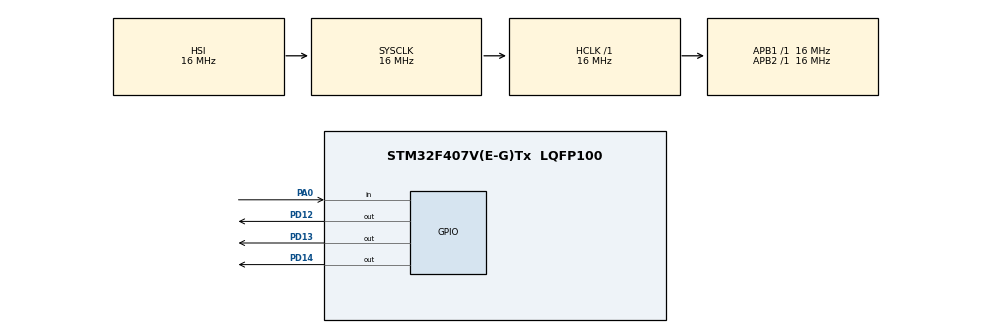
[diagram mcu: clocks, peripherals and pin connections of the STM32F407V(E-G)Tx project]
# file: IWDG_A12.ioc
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Mcu.Family=STM32F4
RCC.CortexFreq_Value=16000000
VP_IWDG_VS_IWDG.Mode=IWDG_Activate
ProjectManager.StackSize=0x400
PA0-WKUP.Signal=GPIO_Input
PD13.Signal=GPIO_Output
PA13.Signal=SYS_JTMS-SWDIO
ProjectManager.TargetToolchain=STM32CubeIDE
RCC.LSE_VALUE=32768
RCC.AHBFreq_Value=16000000
RCC.HSE_VALUE=25000000
board=custom
RCC.VCOOutputFreq_Value=192000000
RCC.APB2Freq_Value=16000000
VP_TIM2_VS_ClockSourceINT.Mode=Internal
PA14.Mode=Serial_Wire
NVIC.TIM2_IRQn=true\:0\:0\:false\:false\:true\:true\:true
TIM2.Period=50
PA13.Mode=Serial_Wire
Mcu.Name=STM32F407V(E-G)Tx
PD14.Signal=GPIO_Output
RCC.SYSCLKFreq_VALUE=16000000
Mcu.Package=LQFP100
TIM2.Prescaler=16000
PD12.Signal=GPIO_Output
PA14.Signal=SYS_JTCK-SWCLK
ProjectManager.HeapSize=0x200
RCC.HSI_VALUE=16000000
NVIC.PriorityGroup=NVIC_PRIORITYGROUP_4
TIM2.TIM_MasterOutputTrigger=TIM_TRGO_UPDATE
IWDG.Prescaler=IWDG_PRESCALER_64
RCC.APB1Freq_Value=16000000

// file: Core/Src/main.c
/* USER CODE BEGIN Header */
/**
  ******************************************************************************
  * @file           : main.c
  * @brief          : Main program body
  ******************************************************************************
  * @attention
  *
  * <h2><center>&copy; Copyright (c) 2021 STMicroelectronics.
  * All rights reserved.</center></h2>
  *
  * This software component is licensed by ST under BSD 3-Clause license,
  * the "License"; You may not use this file except in compliance with the
  * License. You may obtain a copy of the License at:
  *                        opensource.org/licenses/BSD-3-Clause
  *
  ******************************************************************************
  */
/* USER CODE END Header */
#include "main.h"

IWDG_HandleTypeDef hiwdg;

TIM_HandleTypeDef htim2;

/* USER CODE BEGIN PV */
uint32_t counter=0;
/* USER CODE END PV */

void SystemClock_Config(void);
static void MX_GPIO_Init(void);
static void MX_IWDG_Init(void);
static void MX_TIM2_Init(void);

int main(void)
{

  /* MCU Configuration--------------------------------------------------------*/

  /* Reset of all peripherals, Initializes the Flash interface and the Systick. */
  HAL_Init();

  /* Configure the system clock */
  SystemClock_Config();

  /* Initialize all configured peripherals */
  MX_GPIO_Init();
  MX_IWDG_Init();
  MX_TIM2_Init();
  /* USER CODE BEGIN 2 */
  HAL_GPIO_WritePin(GPIOD,GPIO_PIN_14,SET); // For Showing System Reset
  HAL_Delay(2500);
  HAL_TIM_Base_Start_IT(&htim2);
  HAL_GPIO_WritePin(GPIOD,GPIO_PIN_14,RESET);
  /* USER CODE END 2 */

  /* Infinite loop */
  while (1)
  {

    /* USER CODE BEGIN 3 */
	  if(HAL_GPIO_ReadPin(GPIOA,GPIO_PIN_0))
	  	  	  {
	  	  		  HAL_IWDG_Refresh(&hiwdg);
	  	  		  HAL_GPIO_TogglePin(GPIOD,GPIO_PIN_13); //WatchDog Refresh LED
	  	  	  }
  }
  /* USER CODE END 3 */
}

void SystemClock_Config(void)
{
  RCC_OscInitTypeDef RCC_OscInitStruct = {0};
  RCC_ClkInitTypeDef RCC_ClkInitStruct = {0};

  /** Configure the main internal regulator output voltage
  */
  __HAL_RCC_PWR_CLK_ENABLE();
  __HAL_PWR_VOLTAGESCALING_CONFIG(PWR_REGULATOR_VOLTAGE_SCALE1);
  /** Initializes the RCC Oscillators according to the specified parameters
  * in the RCC_OscInitTypeDef structure.
  */
  RCC_OscInitStruct.OscillatorType = RCC_OSCILLATORTYPE_HSI|RCC_OSCILLATORTYPE_LSI;
  RCC_OscInitStruct.HSIState = RCC_HSI_ON;
  RCC_OscInitStruct.HSICalibrationValue = RCC_HSICALIBRATION_DEFAULT;
  RCC_OscInitStruct.LSIState = RCC_LSI_ON;
  RCC_OscInitStruct.PLL.PLLState = RCC_PLL_NONE;
  if (HAL_RCC_OscConfig(&RCC_OscInitStruct) != HAL_OK)
  {
    Error_Handler();
  }
  /** Initializes the CPU, AHB and APB buses clocks
  */
  RCC_ClkInitStruct.ClockType = RCC_CLOCKTYPE_HCLK|RCC_CLOCKTYPE_SYSCLK
                              |RCC_CLOCKTYPE_PCLK1|RCC_CLOCKTYPE_PCLK2;
  RCC_ClkInitStruct.SYSCLKSource = RCC_SYSCLKSOURCE_HSI;
  RCC_ClkInitStruct.AHBCLKDivider = RCC_SYSCLK_DIV1;
  RCC_ClkInitStruct.APB1CLKDivider = RCC_HCLK_DIV1;
  RCC_ClkInitStruct.APB2CLKDivider = RCC_HCLK_DIV1;

  if (HAL_RCC_ClockConfig(&RCC_ClkInitStruct, FLASH_LATENCY_0) != HAL_OK)
  {
    Error_Handler();
  }
}

static void MX_IWDG_Init(void)
{

  hiwdg.Instance = IWDG;
  hiwdg.Init.Prescaler = IWDG_PRESCALER_64;
  hiwdg.Init.Reload = 4095;
  if (HAL_IWDG_Init(&hiwdg) != HAL_OK)
  {
    Error_Handler();
  }

}

static void MX_TIM2_Init(void)
{

  TIM_ClockConfigTypeDef sClockSourceConfig = {0};
  TIM_MasterConfigTypeDef sMasterConfig = {0};

  htim2.Instance = TIM2;
  htim2.Init.Prescaler = 16000;
  htim2.Init.CounterMode = TIM_COUNTERMODE_UP;
  htim2.Init.Period = 50;
  htim2.Init.ClockDivision = TIM_CLOCKDIVISION_DIV1;
  htim2.Init.AutoReloadPreload = TIM_AUTORELOAD_PRELOAD_DISABLE;
  if (HAL_TIM_Base_Init(&htim2) != HAL_OK)
  {
    Error_Handler();
  }
  sClockSourceConfig.ClockSource = TIM_CLOCKSOURCE_INTERNAL;
  if (HAL_TIM_ConfigClockSource(&htim2, &sClockSourceConfig) != HAL_OK)
  {
    Error_Handler();
  }
  sMasterConfig.MasterOutputTrigger = TIM_TRGO_UPDATE;
  sMasterConfig.MasterSlaveMode = TIM_MASTERSLAVEMODE_DISABLE;
  if (HAL_TIMEx_MasterConfigSynchronization(&htim2, &sMasterConfig) != HAL_OK)
  {
    Error_Handler();
  }

}

static void MX_GPIO_Init(void)
{
  GPIO_InitTypeDef GPIO_InitStruct = {0};

  /* GPIO Ports Clock Enable */
  __HAL_RCC_GPIOA_CLK_ENABLE();
  __HAL_RCC_GPIOD_CLK_ENABLE();

  /*Configure GPIO pin Output Level */
  HAL_GPIO_WritePin(GPIOD, GPIO_PIN_12|GPIO_PIN_13|GPIO_PIN_14, GPIO_PIN_RESET);

  /*Configure GPIO pin : PA0 */
  GPIO_InitStruct.Pin = GPIO_PIN_0;
  GPIO_InitStruct.Mode = GPIO_MODE_INPUT;
  GPIO_InitStruct.Pull = GPIO_NOPULL;
  HAL_GPIO_Init(GPIOA, &GPIO_InitStruct);

  /*Configure GPIO pins : PD12 PD13 PD14 */
  GPIO_InitStruct.Pin = GPIO_PIN_12|GPIO_PIN_13|GPIO_PIN_14;
  GPIO_InitStruct.Mode = GPIO_MODE_OUTPUT_PP;
  GPIO_InitStruct.Pull = GPIO_NOPULL;
  GPIO_InitStruct.Speed = GPIO_SPEED_FREQ_LOW;
  HAL_GPIO_Init(GPIOD, &GPIO_InitStruct);

}

/* USER CODE BEGIN 4 */
void HAL_TIM_PeriodElapsedCallback(TIM_HandleTypeDef *htim)
{
	HAL_GPIO_TogglePin(GPIOD,GPIO_PIN_12);// Just for Counting , to show something is running
	counter++;
}
/* USER CODE END 4 */

void Error_Handler(void)
{
  __disable_irq();
  while (1)
  {
  }
}

/************************ (C) COPYRIGHT STMicroelectronics *****END OF FILE****/
